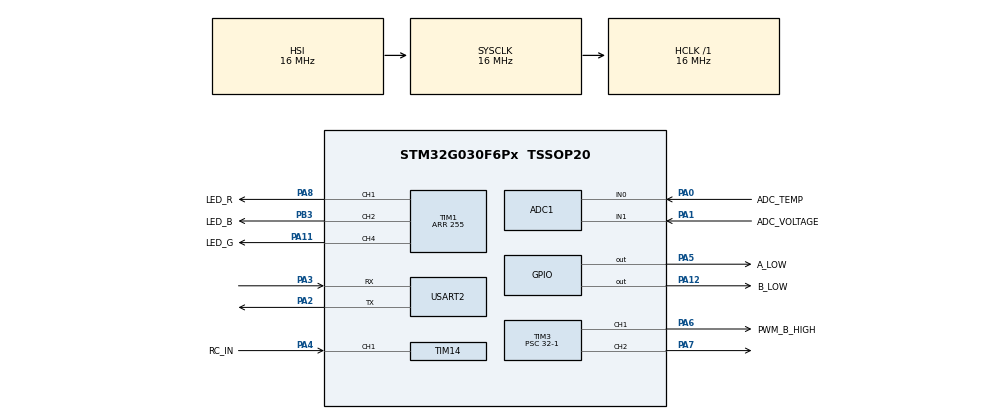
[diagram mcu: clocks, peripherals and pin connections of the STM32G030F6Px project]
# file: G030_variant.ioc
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ADC1.Channel-0\#ChannelRegularConversion=ADC_CHANNEL_0
ADC1.NbrOfConversionFlag=1
ADC1.Rank-0\#ChannelRegularConversion=1
ADC1.SamplingTime-0\#ChannelRegularConversion=ADC_SAMPLINGTIME_COMMON_1
ADC1.SelectedChannel=ADC_CHANNEL_0|ADC_CHANNEL_1
ADC1.master=1
Mcu.Family=STM32G0
Mcu.Name=STM32G030F6Px
Mcu.Package=TSSOP20
NVIC.TIM16_IRQn=true\:0\:0\:false\:false\:true\:true\:true\:true
PA0.GPIO_Label=ADC_TEMP
PA0.Mode=IN0
PA0.Signal=ADC1_IN0
PA1.GPIO_Label=ADC_VOLTAGE
PA1.Mode=IN1
PA1.Signal=ADC1_IN1
PA11\ [PA9].GPIO_Label=LED_G
PA11\ [PA9].Signal=S_TIM1_CH4
PA12\ [PA10].GPIO_Label=B_LOW
PA12\ [PA10].Signal=GPIO_Output
PA13.Mode=Serial_Wire
PA13.Signal=SYS_SWDIO
PA14-BOOT0.Mode=Serial_Wire
PA14-BOOT0.Signal=SYS_SWCLK
PA14-BOOT0__PA15.StandardMode=true
PA2.Mode=Asynchronous
PA2.Signal=USART2_TX
PA3.Mode=Asynchronous
PA3.Signal=USART2_RX
PA4.GPIO_Label=RC_IN
PA4.Signal=S_TIM14_CH1
PA5.GPIO_Label=A_LOW
PA5.Signal=GPIO_Output
PA6.GPIO_Label=PWM_B_HIGH
PA6.Signal=S_TIM3_CH1
PA7.Signal=S_TIM3_CH2
PA8.GPIO_Label=LED_R
PA8.Signal=S_TIM1_CH1
PB0__PB1__PB2__PA8.StandardMode=true
PB3.GPIO_Label=LED_B
PB3.Signal=S_TIM1_CH2
PB3__PB4__PB5__PB6.StandardMode=true
PB7__PB8.StandardMode=true
PC14-OSC32_IN\ (PC14)__PB9.StandardMode=true
ProjectManager.HeapSize=0x200
ProjectManager.StackSize=0x400
ProjectManager.TargetToolchain=STM32CubeIDE
RCC.AHBFreq_Value=16000000
RCC.CortexFreq_Value=16000000
RCC.EXTERNAL_CLOCK_VALUE=12288000
RCC.HCLKFreq_Value=16000000
RCC.HSE_VALUE=8000000
RCC.HSI_VALUE=16000000
RCC.LSE_VALUE=32768
RCC.SYSCLKFreq_VALUE=16000000
RCC.VCOOutputFreq_Value=128000000
SH.S_TIM14_CH1.0=TIM14_CH1,Input_Capture1_from_TI1
SH.S_TIM1_CH1.0=TIM1_CH1,PWM Generation1 CH1
SH.S_TIM1_CH2.0=TIM1_CH2,PWM Generation2 CH2
SH.S_TIM1_CH4.0=TIM1_CH4,PWM Generation4 CH4
SH.S_TIM3_CH1.0=TIM3_CH1,PWM Generation1 CH1
SH.S_TIM3_CH2.0=TIM3_CH2,PWM Generation2 CH2
TIM1.Channel-PWM\ Generation1\ CH1=TIM_CHANNEL_1
TIM1.Channel-PWM\ Generation2\ CH2=TIM_CHANNEL_2
TIM1.Channel-PWM\ Generation4\ CH4=TIM_CHANNEL_4
TIM1.Period=255
TIM14.Channel=TIM_CHANNEL_1
TIM14.ICPolarity_CH1=TIM_INPUTCHANNELPOLARITY_BOTHEDGE
TIM16.Channel=TIM_CHANNEL_1
TIM16.Period=258
TIM16.Prescaler=62
TIM3.AutoReloadPreload=TIM_AUTORELOAD_PRELOAD_DISABLE
TIM3.Channel-PWM\ Generation1\ CH1=TIM_CHANNEL_1
TIM3.Channel-PWM\ Generation2\ CH2=TIM_CHANNEL_2
TIM3.Period=100
TIM3.Prescaler=32-1
USART2.VirtualMode-Asynchronous=VM_ASYNC
VP_TIM14_VS_ClockSourceINT.Mode=Enable_Timer
VP_TIM16_VS_ClockSourceINT.Mode=Enable_Timer
VP_TIM16_VS_no_output1.Mode=PWM Generation1 No Output
board=custom

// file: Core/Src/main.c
/* USER CODE BEGIN Header */
/**
  ******************************************************************************
  * @file           : main.c
  * @brief          : Main program body
  ******************************************************************************
  * @attention
  *
  * <h2><center>&copy; Copyright (c) 2022 STMicroelectronics.
  * All rights reserved.</center></h2>
  *
  * This software component is licensed by ST under BSD 3-Clause license,
  * the "License"; You may not use this file except in compliance with the
  * License. You may obtain a copy of the License at:
  *                        opensource.org/licenses/BSD-3-Clause
  *
  ******************************************************************************
  */
/* USER CODE END Header */
#include "main.h"
#include "adc.h"
#include "tim.h"
#include "usart.h"
#include "gpio.h"

/* USER CODE BEGIN Includes */
#include "control_loop.h"
#include "non_critical_thread.h"
#include "hal_hbridge.h"

/* USER CODE END Includes */

void SystemClock_Config(void);

int main(void)
{

  /* MCU Configuration--------------------------------------------------------*/

  /* Reset of all peripherals, Initializes the Flash interface and the Systick. */
  HAL_Init();

  /* Configure the system clock */
  SystemClock_Config();

  /* Initialize all configured peripherals */
  MX_GPIO_Init();
  MX_ADC1_Init();
  MX_TIM1_Init();
  MX_TIM3_Init();
  MX_TIM14_Init();
  MX_USART2_UART_Init();
  MX_TIM16_Init();
  /* USER CODE BEGIN 2 */
  //HAL_TIM_Base_Start_IT(&htim16);
  control_loop_init();
  init_non_critical_thread();

  /* USER CODE END 2 */

  /* Infinite loop */
  /* USER CODE BEGIN WHILE */
  while (1)
  {
	hal_hbridge_set_speed(-50, false);
	HAL_Delay(1000);
    non_critical_thread_run();
    /* USER CODE END WHILE */

  }
}

void SystemClock_Config(void)
{
  RCC_OscInitTypeDef RCC_OscInitStruct = {0};
  RCC_ClkInitTypeDef RCC_ClkInitStruct = {0};
  RCC_PeriphCLKInitTypeDef PeriphClkInit = {0};

  /** Configure the main internal regulator output voltage
  */
  HAL_PWREx_ControlVoltageScaling(PWR_REGULATOR_VOLTAGE_SCALE1);
  /** Initializes the RCC Oscillators according to the specified parameters
  * in the RCC_OscInitTypeDef structure.
  */
  RCC_OscInitStruct.OscillatorType = RCC_OSCILLATORTYPE_HSI;
  RCC_OscInitStruct.HSIState = RCC_HSI_ON;
  RCC_OscInitStruct.HSIDiv = RCC_HSI_DIV1;
  RCC_OscInitStruct.HSICalibrationValue = RCC_HSICALIBRATION_DEFAULT;
  RCC_OscInitStruct.PLL.PLLState = RCC_PLL_NONE;
  if (HAL_RCC_OscConfig(&RCC_OscInitStruct) != HAL_OK)
  {
    Error_Handler();
  }
  /** Initializes the CPU, AHB and APB buses clocks
  */
  RCC_ClkInitStruct.ClockType = RCC_CLOCKTYPE_HCLK|RCC_CLOCKTYPE_SYSCLK
                              |RCC_CLOCKTYPE_PCLK1;
  RCC_ClkInitStruct.SYSCLKSource = RCC_SYSCLKSOURCE_HSI;
  RCC_ClkInitStruct.AHBCLKDivider = RCC_SYSCLK_DIV1;
  RCC_ClkInitStruct.APB1CLKDivider = RCC_HCLK_DIV1;

  if (HAL_RCC_ClockConfig(&RCC_ClkInitStruct, FLASH_LATENCY_0) != HAL_OK)
  {
    Error_Handler();
  }
  /** Initializes the peripherals clocks
  */
  PeriphClkInit.PeriphClockSelection = RCC_PERIPHCLK_ADC;
  PeriphClkInit.AdcClockSelection = RCC_ADCCLKSOURCE_SYSCLK;
  if (HAL_RCCEx_PeriphCLKConfig(&PeriphClkInit) != HAL_OK)
  {
    Error_Handler();
  }
}

void Error_Handler(void)
{
  __disable_irq();
  while (1)
  {
  }
}

/************************ (C) COPYRIGHT STMicroelectronics *****END OF FILE****/
